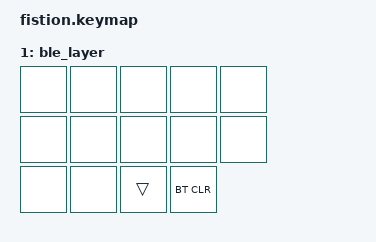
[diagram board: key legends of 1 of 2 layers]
/*
 * Copyright (c) 2020 The ZMK Contributors
 *
 * SPDX-License-Identifier: MIT
 */

#include <behaviors.dtsi>
#include <dt-bindings/zmk/keys.h>
#include <dt-bindings/zmk/bt.h>
#include <dt-bindings/zmk/outputs.h>

/ {
    keymap0: keymap {
        compatible = "zmk,keymap";

        default_layer {
            bindings = <
                &kp A &kp R &kp T &kp S
                &kp E &kp Y &kp I &kp O
                &none &none &mo 1 &none
                >;
        };
        ble_layer {
            bindings = <
                &none &none &none &none &none
                &none &none &none &none &none
                &none &none &trans &bt BT_CLR
                >;
        };
    };
};
